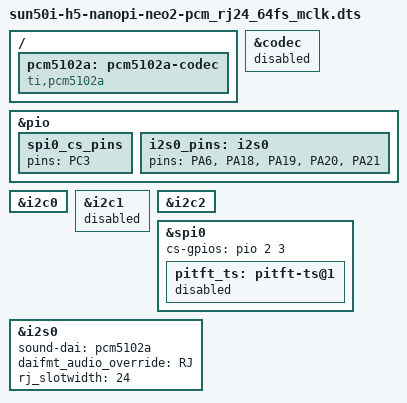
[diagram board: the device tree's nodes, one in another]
/*
 * Copyright (C) 2016 ARM Ltd.
 *
 * This file is dual-licensed: you can use it either under the terms
 * of the GPL or the X11 license, at your option. Note that this dual
 * licensing only applies to this file, and not this project as a
 * whole.
 *
 *  a) This file is free software; you can redistribute it and/or
 *     modify it under the terms of the GNU General Public License as
 *     published by the Free Software Foundation; either version 2 of the
 *     License, or (at your option) any later version.
 *
 *     This file is distributed in the hope that it will be useful,
 *     but WITHOUT ANY WARRANTY; without even the implied warranty of
 *     MERCHANTABILITY or FITNESS FOR A PARTICULAR PURPOSE.  See the
 *     GNU General Public License for more details.
 *
 * Or, alternatively,
 *
 *  b) Permission is hereby granted, free of charge, to any person
 *     obtaining a copy of this software and associated documentation
 *     files (the "Software"), to deal in the Software without
 *     restriction, including without limitation the rights to use,
 *     copy, modify, merge, publish, distribute, sublicense, and/or
 *     sell copies of the Software, and to permit persons to whom the
 *     Software is furnished to do so, subject to the following
 *     conditions:
 *
 *     The above copyright notice and this permission notice shall be
 *     included in all copies or substantial portions of the Software.
 *
 *     THE SOFTWARE IS PROVIDED "AS IS", WITHOUT WARRANTY OF ANY KIND,
 *     EXPRESS OR IMPLIED, INCLUDING BUT NOT LIMITED TO THE WARRANTIES
 *     OF MERCHANTABILITY, FITNESS FOR A PARTICULAR PURPOSE AND
 *     NONINFRINGEMENT. IN NO EVENT SHALL THE AUTHORS OR COPYRIGHT
 *     HOLDERS BE LIABLE FOR ANY CLAIM, DAMAGES OR OTHER LIABILITY,
 *     WHETHER IN AN ACTION OF CONTRACT, TORT OR OTHERWISE, ARISING
 *     FROM, OUT OF OR IN CONNECTION WITH THE SOFTWARE OR THE USE OR
 *     OTHER DEALINGS IN THE SOFTWARE.
 */

/dts-v1/;
#include "sun50i-h5-nanopi-neo2.dts"

/ {
	pcm5102a: pcm5102a-codec {
		#sound-dai-cells = <0>;
		compatible = "ti,pcm5102a";
		status = "okay";
	};
};

&codec {
	status = "disabled";
};

&pio {
	spi0_cs_pins: spi0_cs_pins {
		pins = "PC3";
	};

	i2s0_pins: i2s0 {
		pins = "PA6", "PA18", "PA19", "PA20", "PA21";
	};
};

&i2c0 {
    status = "okay";
};

&i2c1 {
    /* no I2C1 for I2S0 */
    status = "disabled";
};

&i2c2 {
    status = "okay";
};

&spi0 {
    cs-gpios = <&pio 2 3 GPIO_ACTIVE_HIGH>;

    pitft_ts: pitft-ts@1 {
        status = "disabled";
    };
};

&i2s0 {
	sound-dai = <&pcm5102a>;
	status = "okay";
	daifmt_audio_override = "RJ";
	rj_slotwidth = <24>;
};
